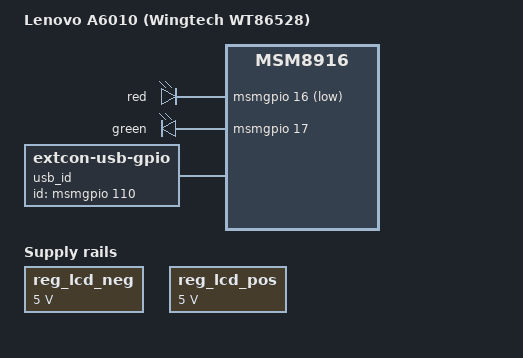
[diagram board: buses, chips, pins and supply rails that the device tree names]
// SPDX-License-Identifier: GPL-2.0-only

/dts-v1/;

#include "msm8916-wingtech-wt865x8.dtsi"

/ {
	model = "Lenovo A6010 (Wingtech WT86528)";
	compatible = "wingtech,wt86528", "qcom,msm8916";
	chassis-type = "handset";

	gpio-leds {
		compatible = "gpio-leds";

		pinctrl-0 = <&gpio_leds_default>;
		pinctrl-names = "default";

		led-0 {
			gpios = <&msmgpio 16 GPIO_ACTIVE_LOW>;
			label = "red";
			default-state = "off";
			retain-state-suspended;
		};

		led-1 {
			gpios = <&msmgpio 17 GPIO_ACTIVE_HIGH>;
			label = "green";
			default-state = "off";
			retain-state-suspended;
		};
	};

	usb_id: usb-id {
		compatible = "linux,extcon-usb-gpio";
		id-gpios = <&msmgpio 110 GPIO_ACTIVE_HIGH>;
		pinctrl-0 = <&usb_id_default>;
		pinctrl-names = "default";
	};
};

&reg_lcd_neg {
	regulator-min-microvolt = <5000000>;
	regulator-max-microvolt = <5000000>;
};

&reg_lcd_pos {
	regulator-min-microvolt = <5000000>;
	regulator-max-microvolt = <5000000>;
};

&usb {
	extcon = <&usb_id>, <&usb_id>;
};

&usb_hs_phy {
	extcon = <&usb_id>;
};

&msmgpio {
	gpio_leds_default: gpio-leds-default-state {
		pins = "gpio16", "gpio17";
		function = "gpio";
		drive-strength = <2>;
		bias-disable;
	};

	usb_id_default: usb-id-default-state {
		pins = "gpio110";
		function = "gpio";
		drive-strength = <8>;
		bias-pull-up;
	};
};
